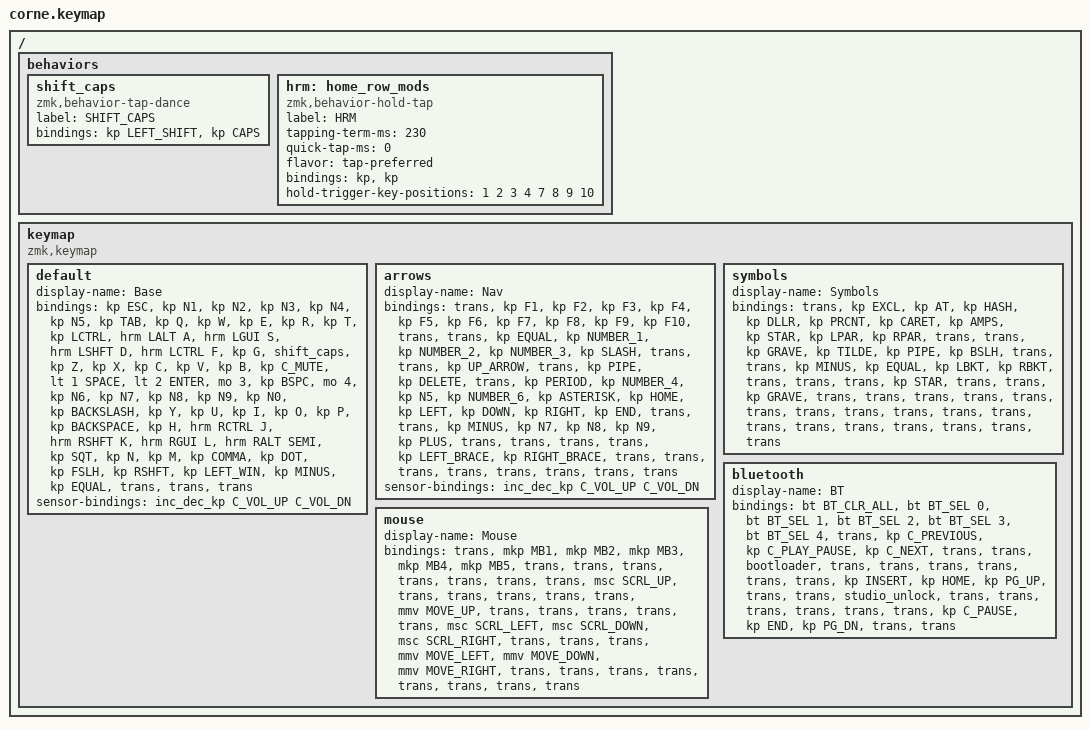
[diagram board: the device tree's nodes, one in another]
/*
 * Eyelash Corne Keymap based on Lily58
 *
 * Rotary encoder = LEFT half (extra key press for C_MUTE)
 * Joystick = RIGHT half (extra keys for MB1/MB2)
 */

#define ZMK_POINTING_DEFAULT_MOVE_VAL 1500
#define ZMK_POINTING_DEFAULT_SCRL_VAL 20

#include <behaviors.dtsi>
#include <dt-bindings/zmk/bt.h>
#include <dt-bindings/zmk/keys.h>
#include <dt-bindings/zmk/pointing.h>

/ {
    behaviors {
        shift_caps: shift_caps {
            compatible = "zmk,behavior-tap-dance";
            label = "SHIFT_CAPS";
            #binding-cells = <0>;
            bindings = <&kp LEFT_SHIFT>, <&kp CAPS>;
        };

        hrm: home_row_mods {
            compatible = "zmk,behavior-hold-tap";
            label = "HRM";
            #binding-cells = <2>;
            tapping-term-ms = <230>;
            quick-tap-ms = <0>;
            flavor = "tap-preferred";
            bindings = <&kp>, <&kp>;
            hold-trigger-key-positions = <1 2 3 4 7 8 9 10>;
        };
    };

    keymap {
        compatible = "zmk,keymap";

        /* =========================================================
         * BASE LAYER
         * ========================================================= */
        default {
            display-name = "Base";

            bindings = <
/* LEFT half */
&kp ESC      &kp N1       &kp N2       &kp N3       &kp N4       &kp N5
&kp TAB      &kp Q        &kp W        &kp E        &kp R        &kp T
&kp LCTRL    &hrm LALT A  &hrm LGUI S  &hrm LSHFT D &hrm LCTRL F &kp G
&shift_caps  &kp Z        &kp X        &kp C        &kp V        &kp B
&kp C_MUTE   &lt 1 SPACE  &lt 2 ENTER  &mo 3        &kp BSPC     &mo 4

/* RIGHT half */
&kp N6       &kp N7       &kp N8       &kp N9       &kp N0       &kp BACKSLASH
&kp Y        &kp U        &kp I        &kp O        &kp P        &kp BACKSPACE
&kp H        &hrm RCTRL J &hrm RSHFT K &hrm RGUI L  &hrm RALT SEMI &kp SQT
&kp N        &kp M        &kp COMMA    &kp DOT      &kp FSLH    &kp RSHFT
&kp LEFT_WIN &kp MINUS    &kp EQUAL    &trans       &trans      &trans
            >;

            /* Rotary encoder rotation on LEFT */
            sensor-bindings = <&inc_dec_kp C_VOL_UP C_VOL_DN>;
        };

        /* =========================================================
         * ARROWS / NAV
         * ========================================================= */
        arrows {
            display-name = "Nav";

            bindings = <
&trans &kp F1 &kp F2 &kp F3 &kp F4 &kp F5          &kp F6 &kp F7 &kp F8 &kp F9 &kp F10 &trans
&trans &kp EQUAL &kp NUMBER_1 &kp NUMBER_2 &kp NUMBER_3 &kp SLASH    &trans &trans &kp UP_ARROW &trans &kp PIPE &kp DELETE
&trans &kp PERIOD &kp NUMBER_4 &kp N5 &kp NUMBER_6 &kp ASTERISK    &kp HOME &kp LEFT &kp DOWN &kp RIGHT &kp END &trans
&trans &kp MINUS &kp N7 &kp N8 &kp N9 &kp PLUS       &trans &trans &trans &trans &kp LEFT_BRACE &kp RIGHT_BRACE &trans &trans
&trans &trans &trans &trans &trans &trans
            >;

            sensor-bindings = <&inc_dec_kp C_VOL_UP C_VOL_DN>;
        };

        /* =========================================================
         * SYMBOLS
         * ========================================================= */
        symbols {
            display-name = "Symbols";

            bindings = <
&trans &kp EXCL &kp AT &kp HASH &kp DLLR &kp PRCNT   &kp CARET &kp AMPS &kp STAR &kp LPAR &kp RPAR &trans
&trans &kp GRAVE &kp TILDE &kp PIPE &kp BSLH &trans  &trans &kp MINUS &kp EQUAL &kp LBKT &kp RBKT &trans
&trans &trans &kp STAR &trans &trans &kp GRAVE &trans &trans &trans &trans &trans &trans
&trans &trans &trans &trans &trans &trans &trans &trans &trans &trans &trans &trans
            >;
        };

        /* =========================================================
         * BLUETOOTH / SYSTEM
         * ========================================================= */
        bluetooth {
            display-name = "BT";

            bindings = <
&bt BT_CLR_ALL &bt BT_SEL 0 &bt BT_SEL 1 &bt BT_SEL 2 &bt BT_SEL 3 &bt BT_SEL 4 &trans &kp C_PREVIOUS &kp C_PLAY_PAUSE &kp C_NEXT &trans &trans
&bootloader &trans &trans &trans &trans &trans &trans &kp INSERT &kp HOME &kp PG_UP &trans &trans
&studio_unlock &trans &trans &trans &trans &trans &trans &kp C_PAUSE &kp END &kp PG_DN &trans &trans
            >;
        };

        /* =========================================================
         * MOUSE / JOYSTICK
         * ========================================================= */
        mouse {
            display-name = "Mouse";

            bindings = <
/* RIGHT half joystick */
&trans &mkp MB1 &mkp MB2 &mkp MB3 &mkp MB4 &mkp MB5 &trans &trans &trans &trans &trans &trans
&trans &msc SCRL_UP &trans &trans &trans &trans &trans &mmv MOVE_UP &trans &trans &trans &trans
&trans &msc SCRL_LEFT &msc SCRL_DOWN &msc SCRL_RIGHT &trans &trans &trans &mmv MOVE_LEFT &mmv MOVE_DOWN &mmv MOVE_RIGHT &trans &trans
&trans &trans &trans &trans &trans &trans
            >;
        };
    };
};
